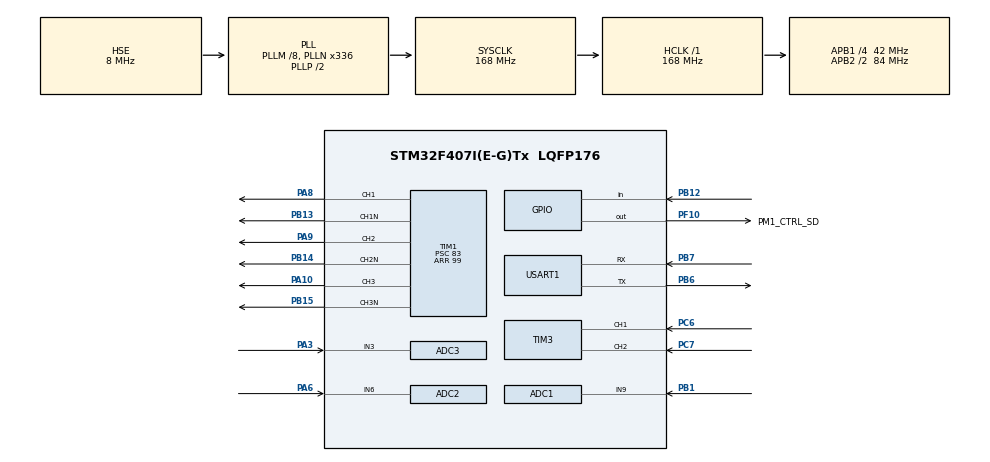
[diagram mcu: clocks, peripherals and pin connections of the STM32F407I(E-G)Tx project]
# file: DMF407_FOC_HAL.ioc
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ADC1.Channel-0\#ChannelRegularConversion=ADC_CHANNEL_9
ADC1.ClockPrescaler=ADC_CLOCK_SYNC_PCLK_DIV4
ADC1.ContinuousConvMode=ENABLE
ADC1.ExternalTrigConv=ADC_EXTERNALTRIGCONV_T1_CC1
ADC1.ExternalTrigConvEdge=ADC_EXTERNALTRIGCONVEDGE_FALLING
ADC1.NbrOfConversionFlag=1
ADC1.Rank-0\#ChannelRegularConversion=1
ADC1.SamplingTime-0\#ChannelRegularConversion=ADC_SAMPLETIME_480CYCLES
ADC1.master=1
ADC2.Channel-0\#ChannelRegularConversion=ADC_CHANNEL_6
ADC2.ContinuousConvMode=ENABLE
ADC2.ExternalTrigConv=ADC_EXTERNALTRIGCONV_T1_CC1
ADC2.ExternalTrigConvEdge=ADC_EXTERNALTRIGCONVEDGE_FALLING
ADC2.InjNumberOfConversion=0
ADC2.NbrOfConversionFlag=1
ADC2.Rank-0\#ChannelRegularConversion=1
ADC2.SamplingTime-0\#ChannelRegularConversion=ADC_SAMPLETIME_480CYCLES
ADC3.Channel-1\#ChannelRegularConversion=ADC_CHANNEL_3
ADC3.ContinuousConvMode=ENABLE
ADC3.ExternalTrigConv=ADC_EXTERNALTRIGCONV_T1_CC1
ADC3.ExternalTrigConvEdge=ADC_EXTERNALTRIGCONVEDGE_FALLING
ADC3.NbrOfConversionFlag=1
ADC3.Rank-1\#ChannelRegularConversion=1
ADC3.SamplingTime-1\#ChannelRegularConversion=ADC_SAMPLETIME_480CYCLES
Mcu.Family=STM32F4
Mcu.Name=STM32F407I(E-G)Tx
Mcu.Package=LQFP176
NVIC.PriorityGroup=NVIC_PRIORITYGROUP_4
NVIC.TIM1_UP_TIM10_IRQn=true\:0\:0\:false\:false\:true\:true\:true\:true
NVIC.TIM2_IRQn=true\:1\:0\:true\:false\:true\:true\:true\:true
NVIC.TIM3_IRQn=true\:1\:0\:true\:false\:true\:true\:true\:true
NVIC.TIM4_IRQn=true\:1\:0\:true\:false\:true\:true\:true\:true
PA10.GPIO_PuPd=GPIO_PULLDOWN
PA10.GPIO_Speed=GPIO_SPEED_FREQ_HIGH
PA10.Signal=S_TIM1_CH3
PA13.Mode=Serial_Wire
PA13.Signal=SYS_JTMS-SWDIO
PA14.Mode=Serial_Wire
PA14.Signal=SYS_JTCK-SWCLK
PA3.Signal=ADCx_IN3
PA6.Signal=ADCx_IN6
PA8.GPIO_PuPd=GPIO_PULLDOWN
PA8.GPIO_Speed=GPIO_SPEED_FREQ_HIGH
PA8.Signal=S_TIM1_CH1
PA9.GPIO_PuPd=GPIO_PULLDOWN
PA9.GPIO_Speed=GPIO_SPEED_FREQ_HIGH
PA9.Signal=S_TIM1_CH2
PB1.Signal=ADCx_IN9
PB12.GPIO_PuPd=GPIO_NOPULL
PB12.Signal=GPIO_Input
PB13.GPIO_PuPd=GPIO_PULLDOWN
PB13.GPIO_Speed=GPIO_SPEED_FREQ_HIGH
PB13.Mode=PWM Generation1 CH1 CH1N
PB13.Signal=TIM1_CH1N
PB14.GPIO_PuPd=GPIO_PULLDOWN
PB14.GPIO_Speed=GPIO_SPEED_FREQ_HIGH
PB14.Mode=PWM Generation2 CH2 CH2N
PB14.Signal=TIM1_CH2N
PB15.GPIO_PuPd=GPIO_PULLDOWN
PB15.GPIO_Speed=GPIO_SPEED_FREQ_HIGH
PB15.Mode=PWM Generation3 CH3 CH3N
PB15.Signal=TIM1_CH3N
PB6.GPIO_Speed=GPIO_SPEED_FREQ_HIGH
PB6.Mode=Asynchronous
PB6.Signal=USART1_TX
PB7.GPIO_Speed=GPIO_SPEED_FREQ_HIGH
PB7.Mode=Asynchronous
PB7.Signal=USART1_RX
PC6.GPIO_Speed=GPIO_SPEED_FREQ_HIGH
PC6.Signal=S_TIM3_CH1
PC7.GPIO_Speed=GPIO_SPEED_FREQ_HIGH
PC7.Signal=S_TIM3_CH2
PF10.GPIO_Label=PM1_CTRL_SD
PF10.GPIO_PuPd=GPIO_PULLDOWN
PF10.GPIO_Speed=GPIO_SPEED_FREQ_HIGH
PF10.PinState=GPIO_PIN_RESET
PF10.Signal=GPIO_Output
PH0-OSC_IN.Mode=HSE-External-Oscillator
PH0-OSC_IN.Signal=RCC_OSC_IN
PH1-OSC_OUT.Mode=HSE-External-Oscillator
PH1-OSC_OUT.Signal=RCC_OSC_OUT
ProjectManager.HeapSize=0x200
ProjectManager.StackSize=0x400
ProjectManager.TargetToolchain=CMake
RCC.48MHZClocksFreq_Value=48000000
RCC.AHBFreq_Value=168000000
RCC.APB1CLKDivider=RCC_HCLK_DIV4
RCC.APB1Freq_Value=42000000
RCC.APB1TimFreq_Value=84000000
RCC.APB2CLKDivider=RCC_HCLK_DIV2
RCC.APB2Freq_Value=84000000
RCC.APB2TimFreq_Value=168000000
RCC.CortexFreq_Value=168000000
RCC.HCLKFreq_Value=168000000
RCC.HSE_VALUE=8000000
RCC.HSI_VALUE=16000000
RCC.LSE_VALUE=32768
RCC.PLLM=8
RCC.PLLN=336
RCC.PLLQ=7
RCC.PLLSourceVirtual=RCC_PLLSOURCE_HSE
RCC.SYSCLKFreq_VALUE=168000000
RCC.SYSCLKSource=RCC_SYSCLKSOURCE_PLLCLK
RCC.VCOOutputFreq_Value=336000000
SH.ADCx_IN3.0=ADC3_IN3,IN3
SH.ADCx_IN6.0=ADC2_IN6,IN6
SH.ADCx_IN9.0=ADC1_IN9,IN9
SH.S_TIM1_CH1.0=TIM1_CH1,PWM Generation1 CH1 CH1N
SH.S_TIM1_CH2.0=TIM1_CH2,PWM Generation2 CH2 CH2N
SH.S_TIM1_CH3.0=TIM1_CH3,PWM Generation3 CH3 CH3N
SH.S_TIM3_CH1.0=TIM3_CH1,Encoder_Interface
SH.S_TIM3_CH2.0=TIM3_CH2,Encoder_Interface
TIM1.AutoReloadPreload=TIM_AUTORELOAD_PRELOAD_ENABLE
TIM1.BreakState=TIM_BREAK_ENABLE
TIM1.Channel-PWM\ Generation1\ CH1\ CH1N=TIM_CHANNEL_1
TIM1.Channel-PWM\ Generation2\ CH2\ CH2N=TIM_CHANNEL_2
TIM1.Channel-PWM\ Generation3\ CH3\ CH3N=TIM_CHANNEL_3
TIM1.CounterMode=TIM_COUNTERMODE_CENTERALIGNED1
TIM1.DeadTime=84
TIM1.LockLevel=TIM_LOCKLEVEL_1
TIM1.Period=99
TIM1.Prescaler=83
TIM1.TIM_MasterOutputTrigger=TIM_TRGO_OC1REF
TIM2.Period=999
TIM2.Prescaler=83
TIM3.EncoderMode=TIM_ENCODERMODE_TI12
TIM3.IC1Filter=4
TIM3.IC2Filter=4
TIM4.Period=10000
TIM4.Prescaler=10
USART1.VirtualMode=VM_ASYNC
VP_TIM1_VS_ClockSourceINT.Mode=Internal
VP_TIM2_VS_ClockSourceINT.Mode=Internal
VP_TIM4_VS_ClockSourceINT.Mode=Internal
board=custom

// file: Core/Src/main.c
/* USER CODE BEGIN Header */
/**
  ******************************************************************************
  * @file           : main.c
  * @brief          : Main program body
  ******************************************************************************
  * @attention
  *
  * Copyright (c) 2026 STMicroelectronics.
  * All rights reserved.
  *
  * This software is licensed under terms that can be found in the LICENSE file
  * in the root directory of this software component.
  * If no LICENSE file comes with this software, it is provided AS-IS.
  *
  ******************************************************************************
  */
/* USER CODE END Header */
#include "main.h"
#include "adc.h"
#include "tim.h"
#include "usart.h"
#include "gpio.h"

/* USER CODE BEGIN Includes */
#include "bsp_pwm.h"
#include "bsp_adc.h"
#include "bsp_encoder.h"
#include "bsp_timer.h"
#include "bsp_motor_enable.h"
#include "app_no_power.h"
#include "bsp_safety.h"
/* USER CODE END Includes */

void SystemClock_Config(void);

int main(void)
{

  /* MCU Configuration--------------------------------------------------------*/

  /* Reset of all peripherals, Initializes the Flash interface and the Systick. */
  HAL_Init();

  /* Configure the system clock */
  SystemClock_Config();

  /* Initialize all configured peripherals */
  MX_GPIO_Init();
  MX_ADC1_Init();
  MX_ADC2_Init();
  MX_ADC3_Init();
  MX_TIM1_Init();
  MX_TIM2_Init();
  MX_TIM3_Init();
  MX_TIM4_Init();
  MX_USART1_UART_Init();
  /* USER CODE BEGIN 2 */
  /* D-20 安全例外：MX_GPIO_Init 已在切换输出模式前预置 PF10 Low，
   * 此处通过 BSP 重复发送图纸所示目标禁止态，先于所有 BSP 启动。
   * 实板极性/R70/保护链未验收：POWER-STAGE ENABLE BLOCKED。 */
  BSP_MotorEnable_ForceDisable();

  /* V2 checked no-power startup; normal timer/ADC configuration is unchanged.
   * Default firmware runs diagnostics only. Full control replay is opt-in,
   * keeps PF10 Low, and still requires physically disconnected power bus. */
  if (!App_NoPower_Start())
  {
    Error_Handler();
  }
  /* USER CODE END 2 */

  /* Infinite loop */
  while (1)
  {

    /* USER CODE BEGIN 3 */
    App_NoPower_Poll();
  }
  /* USER CODE END 3 */
}

void SystemClock_Config(void)
{
  RCC_OscInitTypeDef RCC_OscInitStruct = {0};
  RCC_ClkInitTypeDef RCC_ClkInitStruct = {0};

  /** Configure the main internal regulator output voltage
  */
  __HAL_RCC_PWR_CLK_ENABLE();
  __HAL_PWR_VOLTAGESCALING_CONFIG(PWR_REGULATOR_VOLTAGE_SCALE1);

  /** Initializes the RCC Oscillators according to the specified parameters
  * in the RCC_OscInitTypeDef structure.
  */
  RCC_OscInitStruct.OscillatorType = RCC_OSCILLATORTYPE_HSE;
  RCC_OscInitStruct.HSEState = RCC_HSE_ON;
  RCC_OscInitStruct.PLL.PLLState = RCC_PLL_ON;
  RCC_OscInitStruct.PLL.PLLSource = RCC_PLLSOURCE_HSE;
  RCC_OscInitStruct.PLL.PLLM = 8;
  RCC_OscInitStruct.PLL.PLLN = 336;
  RCC_OscInitStruct.PLL.PLLP = RCC_PLLP_DIV2;
  RCC_OscInitStruct.PLL.PLLQ = 7;
  if (HAL_RCC_OscConfig(&RCC_OscInitStruct) != HAL_OK)
  {
    Error_Handler();
  }

  /** Initializes the CPU, AHB and APB buses clocks
  */
  RCC_ClkInitStruct.ClockType = RCC_CLOCKTYPE_HCLK|RCC_CLOCKTYPE_SYSCLK
                              |RCC_CLOCKTYPE_PCLK1|RCC_CLOCKTYPE_PCLK2;
  RCC_ClkInitStruct.SYSCLKSource = RCC_SYSCLKSOURCE_PLLCLK;
  RCC_ClkInitStruct.AHBCLKDivider = RCC_SYSCLK_DIV1;
  RCC_ClkInitStruct.APB1CLKDivider = RCC_HCLK_DIV4;
  RCC_ClkInitStruct.APB2CLKDivider = RCC_HCLK_DIV2;

  if (HAL_RCC_ClockConfig(&RCC_ClkInitStruct, FLASH_LATENCY_5) != HAL_OK)
  {
    Error_Handler();
  }
}

/* USER CODE BEGIN 4 */
/* TIM 更新中断统一分发已迁至 BSP/bsp_timer.c
 * （HAL_TIM_PeriodElapsedCallback 覆盖 HAL 弱定义，TIM1/TIM2/TIM3/TIM4 分支在该文件内）。
 * 本处保持为空，不得再定义同名回调，否则链接期重复定义。 */
/* USER CODE END 4 */

void Error_Handler(void)
{
  /* USER CODE BEGIN Error_Handler_Debug */
  /* Gate first, even if clock/peripheral setup failed. */
  __HAL_RCC_GPIOF_CLK_ENABLE();
  BSP_Safety_Fault(BSP_FAULT_INIT);
  __disable_irq();
  while (1)
  {
  }
  /* USER CODE END Error_Handler_Debug */
}
